# nrf52805 register map
Vendor: Nordic Semiconductor; Series: nrf52; File version: 1
CPU: CM4 r0p1, little endian, MPU, no FPU, 3 interrupt priority bits
Registers are 32-bit, read-write, reset 0x0 unless marked. A register's access mark holds for its fields unless they carry their own. Offsets are from the block's base; [hi:lo] are bit positions; {n}, {i} and the like mark numbered series; 'fields as' and 'values as' point back to an identical list.

## RADIO — 2.4 GHz radio
Base 0x40001000
0x00 TASKS_TXEN wo — Enable RADIO in TX mode
  [0] TASKS_TXEN
    1=Trigger task
0x04 TASKS_RXEN wo — Enable RADIO in RX mode
  [0] TASKS_RXEN
    1=Trigger task
0x08 TASKS_START wo — Start RADIO
  [0] TASKS_START
    1=Trigger task
0x0C TASKS_STOP wo — Stop RADIO
  [0] TASKS_STOP
    1=Trigger task
0x10 TASKS_DISABLE wo — Disable RADIO
  [0] TASKS_DISABLE
    1=Trigger task
0x14 TASKS_RSSISTART wo — Start the RSSI and take one single sample of the receive signal strength
  [0] TASKS_RSSISTART
    1=Trigger task
0x18 TASKS_RSSISTOP wo — Stop the RSSI measurement
  [0] TASKS_RSSISTOP
    1=Trigger task
0x1C TASKS_BCSTART wo — Start the bit counter
  [0] TASKS_BCSTART
    1=Trigger task
0x20 TASKS_BCSTOP wo — Stop the bit counter
  [0] TASKS_BCSTOP
    1=Trigger task
0x100 EVENTS_READY — RADIO has ramped up and is ready to be started
  [0] EVENTS_READY
    0=NotGenerated (Event not generated); 1=Generated (Event generated)
0x104 EVENTS_ADDRESS — Address sent or received
  [0] EVENTS_ADDRESS
    values as EVENTS_READY.EVENTS_READY
0x108 EVENTS_PAYLOAD — Packet payload sent or received
  [0] EVENTS_PAYLOAD
    values as EVENTS_READY.EVENTS_READY
0x10C EVENTS_END — Packet sent or received
  [0] EVENTS_END
    values as EVENTS_READY.EVENTS_READY
0x110 EVENTS_DISABLED — RADIO has been disabled
  [0] EVENTS_DISABLED
    values as EVENTS_READY.EVENTS_READY
0x114 EVENTS_DEVMATCH — A device address match occurred on the last received packet
  [0] EVENTS_DEVMATCH
    values as EVENTS_READY.EVENTS_READY
0x118 EVENTS_DEVMISS — No device address match occurred on the last received packet
  [0] EVENTS_DEVMISS
    values as EVENTS_READY.EVENTS_READY
0x11C EVENTS_RSSIEND — Sampling of receive signal strength complete
  [0] EVENTS_RSSIEND
    values as EVENTS_READY.EVENTS_READY
0x128 EVENTS_BCMATCH — Bit counter reached bit count value
  [0] EVENTS_BCMATCH
    values as EVENTS_READY.EVENTS_READY
0x130 EVENTS_CRCOK — Packet received with CRC ok
  [0] EVENTS_CRCOK
    values as EVENTS_READY.EVENTS_READY
0x134 EVENTS_CRCERROR — Packet received with CRC error
  [0] EVENTS_CRCERROR
    values as EVENTS_READY.EVENTS_READY
0x154 EVENTS_TXREADY — RADIO has ramped up and is ready to be started TX path
  [0] EVENTS_TXREADY
    values as EVENTS_READY.EVENTS_READY
0x158 EVENTS_RXREADY — RADIO has ramped up and is ready to be started RX path
  [0] EVENTS_RXREADY
    values as EVENTS_READY.EVENTS_READY
0x15C EVENTS_MHRMATCH — MAC header match found
  [0] EVENTS_MHRMATCH
    values as EVENTS_READY.EVENTS_READY
0x16C EVENTS_PHYEND — Generated when last bit is sent on air
  [0] EVENTS_PHYEND
    values as EVENTS_READY.EVENTS_READY
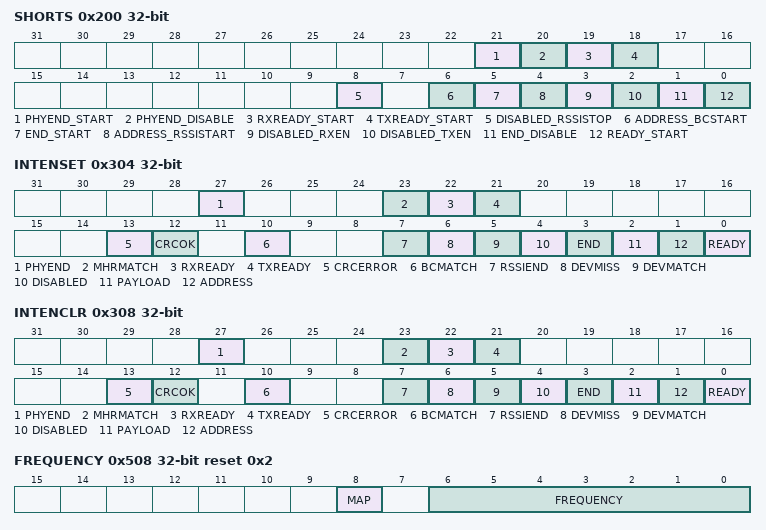
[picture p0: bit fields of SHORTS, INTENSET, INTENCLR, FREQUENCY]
0x200 SHORTS — Shortcuts between local events and tasks
  [all] fields
    0=Disabled (Disable shortcut); 1=Enabled (Enable shortcut)
  [21] PHYEND_START — Shortcut between event PHYEND and task START
  [20] PHYEND_DISABLE — Shortcut between event PHYEND and task DISABLE
  [19] RXREADY_START — Shortcut between event RXREADY and task START
  [18] TXREADY_START — Shortcut between event TXREADY and task START
  [8] DISABLED_RSSISTOP — Shortcut between event DISABLED and task RSSISTOP
  [6] ADDRESS_BCSTART — Shortcut between event ADDRESS and task BCSTART
  [5] END_START — Shortcut between event END and task START
  [4] ADDRESS_RSSISTART — Shortcut between event ADDRESS and task RSSISTART
  [3] DISABLED_RXEN — Shortcut between event DISABLED and task RXEN
  [2] DISABLED_TXEN — Shortcut between event DISABLED and task TXEN
  [1] END_DISABLE — Shortcut between event END and task DISABLE
  [0] READY_START — Shortcut between event READY and task START
0x304 INTENSET — Enable interrupt
  [all] fields
    on read: 0=Disabled (Read: Disabled); 1=Enabled (Read: Enabled) | on write: 1=Set (Enable)
  [27] PHYEND — Write '1' to enable interrupt for event PHYEND
  [23] MHRMATCH — Write '1' to enable interrupt for event MHRMATCH
  [22] RXREADY — Write '1' to enable interrupt for event RXREADY
  [21] TXREADY — Write '1' to enable interrupt for event TXREADY
  [13] CRCERROR — Write '1' to enable interrupt for event CRCERROR
  [12] CRCOK — Write '1' to enable interrupt for event CRCOK
  [10] BCMATCH — Write '1' to enable interrupt for event BCMATCH
  [7] RSSIEND — Write '1' to enable interrupt for event RSSIEND
  [6] DEVMISS — Write '1' to enable interrupt for event DEVMISS
  [5] DEVMATCH — Write '1' to enable interrupt for event DEVMATCH
  [4] DISABLED — Write '1' to enable interrupt for event DISABLED
  [3] END — Write '1' to enable interrupt for event END
  [2] PAYLOAD — Write '1' to enable interrupt for event PAYLOAD
  [1] ADDRESS — Write '1' to enable interrupt for event ADDRESS
  [0] READY — Write '1' to enable interrupt for event READY
0x308 INTENCLR — Disable interrupt
  [all] fields
    on read: 0=Disabled (Read: Disabled); 1=Enabled (Read: Enabled) | on write: 1=Clear (Disable)
  [27] PHYEND — Write '1' to disable interrupt for event PHYEND
  [23] MHRMATCH — Write '1' to disable interrupt for event MHRMATCH
  [22] RXREADY — Write '1' to disable interrupt for event RXREADY
  [21] TXREADY — Write '1' to disable interrupt for event TXREADY
  [13] CRCERROR — Write '1' to disable interrupt for event CRCERROR
  [12] CRCOK — Write '1' to disable interrupt for event CRCOK
  [10] BCMATCH — Write '1' to disable interrupt for event BCMATCH
  [7] RSSIEND — Write '1' to disable interrupt for event RSSIEND
  [6] DEVMISS — Write '1' to disable interrupt for event DEVMISS
  [5] DEVMATCH — Write '1' to disable interrupt for event DEVMATCH
  [4] DISABLED — Write '1' to disable interrupt for event DISABLED
  [3] END — Write '1' to disable interrupt for event END
  [2] PAYLOAD — Write '1' to disable interrupt for event PAYLOAD
  [1] ADDRESS — Write '1' to disable interrupt for event ADDRESS
  [0] READY — Write '1' to disable interrupt for event READY
0x400 CRCSTATUS ro
  [0] CRCSTATUS — CRC status of packet received
    0=CRCError (Packet received with CRC error); 1=CRCOk (Packet received with CRC ok)
0x408 RXMATCH ro — Received address
  [2:0] RXMATCH
0x40C RXCRC ro — CRC field of previously received packet
  [23:0] RXCRC
0x410 DAI ro — Device address match index
  [2:0] DAI
0x414 PDUSTAT ro — Payload status
  [0] PDUSTAT — Status on payload length vs. PCNF1.MAXLEN
    0=LessThan (Payload less than PCNF1.MAXLEN); 1=GreaterThan (Payload greater than PCNF1.MAXLEN)
0x504 PACKETPTR — Packet pointer
0x508 FREQUENCY reset 0x2
  [8] MAP — Channel map selection.
    0=Default (Channel map between 2400 MHZ .. 2500 MHz); 1=Low (Channel map between 2360 MHZ .. 2460 MHz)
  [6:0] FREQUENCY — Radio channel frequency
0x50C TXPOWER — Output power
  [7:0] TXPOWER — RADIO output power
    4=Pos4dBm (+4 dBm); 3=Pos3dBm (+3 dBm); 0=0dBm; 252=Neg4dBm (-4 dBm); 248=Neg8dBm (-8 dBm); 244=Neg12dBm (-12 dBm); 240=Neg16dBm (-16 dBm); 236=Neg20dBm (-20 dBm); 226=Neg30dBm (Deprecated enumerator - -40 dBm); 216=Neg40dBm (-40 dBm)
0x510 MODE — Data rate and modulation
  [3:0] MODE — Radio data rate and modulation setting. The radio supports frequency-shift keying (FSK) modulation.
    0=Nrf_1Mbit (1 Mbps Nordic proprietary radio mode); 1=Nrf_2Mbit (2 Mbps Nordic proprietary radio mode); 3=Ble_1Mbit (1 Mbps BLE); 4=Ble_2Mbit (2 Mbps BLE)
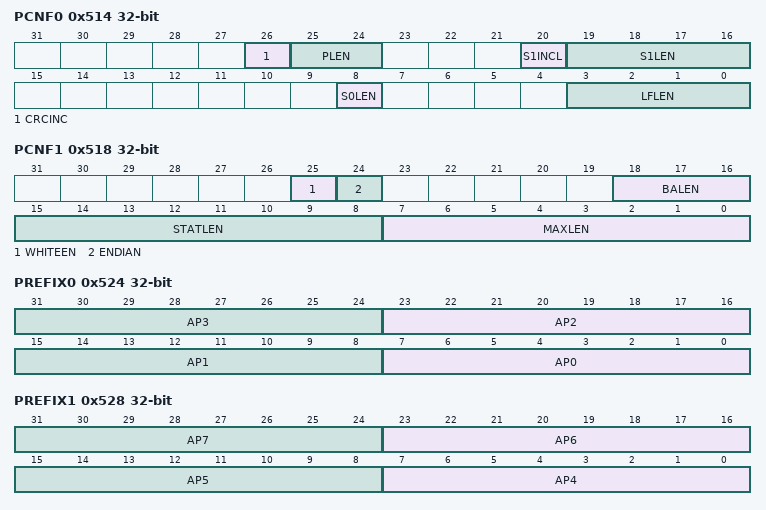
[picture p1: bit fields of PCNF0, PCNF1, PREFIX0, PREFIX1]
0x514 PCNF0 — Packet configuration register 0
  [26] CRCINC — Indicates if LENGTH field contains CRC or not
    0=Exclude (LENGTH does not contain CRC); 1=Include (LENGTH includes CRC)
  [25:24] PLEN — Length of preamble on air. Decision point: TASKS_START task
    0=8-bit preamble; 1=16-bit preamble
  [20] S1INCL — Include or exclude S1 field in RAM
    0=Automatic (Include S1 field in RAM only if S1LEN > 0); 1=Include (Always include S1 field in RAM independent of S1LEN)
  [19:16] S1LEN — Length on air of S1 field in number of bits.
  [8] S0LEN — Length on air of S0 field in number of bytes.
  [3:0] LFLEN — Length on air of LENGTH field in number of bits.
0x518 PCNF1 — Packet configuration register 1
  [25] WHITEEN — Enable or disable packet whitening
    0=Disabled; 1=Enabled
  [24] ENDIAN — On-air endianness of packet, this applies to the S0, LENGTH, S1, and the PAYLOAD fields.
    0=Little (Least significant bit on air first); 1=Big (Most significant bit on air first)
  [18:16] BALEN — Base address length in number of bytes
  [15:8] STATLEN — Static length in number of bytes
  [7:0] MAXLEN — Maximum length of packet payload. If the packet payload is larger than MAXLEN, the radio will truncate the payload to MAXLEN.
0x51C BASE0 — Base address 0
0x520 BASE1 — Base address 1
0x524 PREFIX0 — Prefixes bytes for logical addresses 0-3
  [8n+7:8n] AP{n} (n=0..3) — Address prefix {n}.
0x528 PREFIX1 — Prefixes bytes for logical addresses 4-7
  [8n-25:8n-32] AP{n} (n=4..7) — Address prefix {n}.
0x52C TXADDRESS — Transmit address select
  [2:0] TXADDRESS
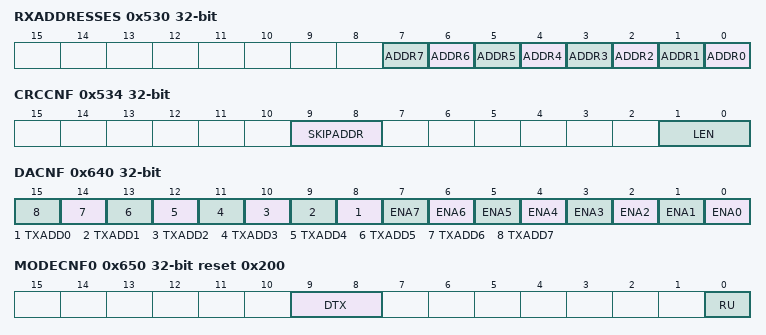
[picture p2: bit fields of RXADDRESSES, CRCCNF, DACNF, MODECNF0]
0x530 RXADDRESSES — Receive address select
  [all] fields
    0=Disabled; 1=Enabled
  [n] ADDR{n} (n=0..7) — Enable or disable reception on logical address {n}.
0x534 CRCCNF — CRC configuration
  [9:8] SKIPADDR — Include or exclude packet address field out of CRC calculation.
    0=Include (CRC calculation includes address field); 1=Skip (CRC calculation does not include address field. The CRC calculation will start at the first byte after the address.)
  [1:0] LEN — CRC length in number of bytes.
    0=Disabled (CRC length is zero and CRC calculation is disabled); 1=One (CRC length is one byte and CRC calculation is enabled); 2=Two (CRC length is two bytes and CRC calculation is enabled); 3=Three (CRC length is three bytes and CRC calculation is enabled)
0x538 CRCPOLY — CRC polynomial
  [23:0] CRCPOLY
0x53C CRCINIT — CRC initial value
  [23:0] CRCINIT
0x544 TIFS — Interframe spacing in us
  [9:0] TIFS
0x548 RSSISAMPLE ro
  [6:0] RSSISAMPLE
0x550 STATE ro — Current radio state
  [3:0] STATE
    0=Disabled (RADIO is in the Disabled state); 1=RxRu (RADIO is in the RXRU state); 2=RxIdle (RADIO is in the RXIDLE state); 3=Rx (RADIO is in the RX state); 4=RxDisable (RADIO is in the RXDISABLED state); 9=TxRu (RADIO is in the TXRU state); 10=TxIdle (RADIO is in the TXIDLE state); 11=Tx (RADIO is in the TX state); 12=TxDisable (RADIO is in the TXDISABLED state)
0x554 DATAWHITEIV reset 0x40 — Data whitening initial value
  [6:0] DATAWHITEIV — Data whitening initial value. Bit 6 is hardwired to '1', writing '0' to it has no effect, and it will always be read back and used by the device as '1'.
0x560 BCC — Bit counter compare
{0x600+4i} DAB[{i}] (i=0..7) — Description collection: Device address base segment n
  [31:0] DAB — Device address base segment n
{0x620+4i} DAP[{i}] (i=0..7) — Description collection: Device address prefix n
  [15:0] DAP — Device address prefix n
0x640 DACNF — Device address match configuration
  [n+8] TXADD{n} (n=0..7) — TxAdd for device address {n}
  [n] ENA{n} (n=0..7) — Enable or disable device address matching using device address {n}
    0=Disabled; 1=Enabled
0x650 MODECNF0 reset 0x200 — Radio mode configuration register 0
  [9:8] DTX — Default TX value
    0=B1 (Transmit '1'); 1=B0 (Transmit '0'); 2=Center (Transmit center frequency)
  [0] RU — Radio ramp-up time
    0=Default ramp-up time (tRXEN and tTXEN), compatible with firmware written for nRF51; 1=Fast ramp-up (tRXEN,FAST and tTXEN,FAST), see electrical specification for more information
0xFFC POWER reset 0x1 — Peripheral power control
  [0] POWER — Peripheral power control. The peripheral and its registers will be reset to its initial state by switching the peripheral off and then back on again.
    0=Disabled (Peripheral is powered off); 1=Enabled (Peripheral is powered on)

## Notices in the file
Copyright (c) 2010 - 2018, Nordic Semiconductor ASA All rights reserved.
Redistribution and use in source and binary forms, with or without
modification, are permitted provided that the following conditions are met:
1. Redistributions of source code must retain the above copyright notice, this
list of conditions and the following disclaimer.
2. Redistributions in binary form must reproduce the above copyright
notice, this list of conditions and the following disclaimer in the
documentation and/or other materials provided with the distribution.
3. Neither the name of Nordic Semiconductor ASA nor the names of its
contributors may be used to endorse or promote products derived from this
software without specific prior written permission.
THIS SOFTWARE IS PROVIDED BY THE COPYRIGHT HOLDERS AND CONTRIBUTORS "AS IS"
AND ANY EXPRESS OR IMPLIED WARRANTIES, INCLUDING, BUT NOT LIMITED TO, THE
IMPLIED WARRANTIES OF MERCHANTABILITY, AND FITNESS FOR A PARTICULAR PURPOSE
ARE DISCLAIMED. IN NO EVENT SHALL NORDIC SEMICONDUCTOR ASA OR CONTRIBUTORS BE
LIABLE FOR ANY DIRECT, INDIRECT, INCIDENTAL, SPECIAL, EXEMPLARY, OR
CONSEQUENTIAL DAMAGES (INCLUDING, BUT NOT LIMITED TO, PROCUREMENT OF
SUBSTITUTE GOODS OR SERVICES; LOSS OF USE, DATA, OR PROFITS; OR BUSINESS
INTERRUPTION) HOWEVER CAUSED AND ON ANY THEORY OF LIABILITY, WHETHER IN
CONTRACT, STRICT LIABILITY, OR TORT (INCLUDING NEGLIGENCE OR OTHERWISE)
ARISING IN ANY WAY OUT OF THE USE OF THIS SOFTWARE, EVEN IF ADVISED OF THE
POSSIBILITY OF SUCH DAMAGE.
